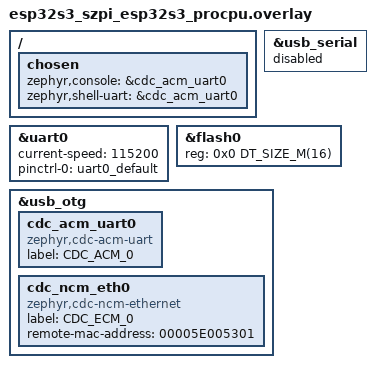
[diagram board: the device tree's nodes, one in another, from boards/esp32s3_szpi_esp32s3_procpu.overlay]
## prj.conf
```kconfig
CONFIG_NETWORKING=y
CONFIG_NET_ZPERF=y
CONFIG_NET_ZPERF_SERVER=y
CONFIG_NET_LOG=y
CONFIG_NET_IPV6=y
CONFIG_NET_IPV4=y
CONFIG_NET_DHCPV4=n
CONFIG_NET_UDP=y
CONFIG_NET_TCP=y
CONFIG_NET_TCP_IPV6_ND_REACHABILITY_HINT=y
CONFIG_NET_STATISTICS=y

CONFIG_NET_PKT_RX_COUNT=40
CONFIG_NET_PKT_TX_COUNT=40
CONFIG_NET_BUF_RX_COUNT=160
CONFIG_NET_BUF_TX_COUNT=160
CONFIG_NET_BUF_DATA_SIZE=256
CONFIG_NET_IF_UNICAST_IPV6_ADDR_COUNT=4
CONFIG_NET_IF_MCAST_IPV6_ADDR_COUNT=5
CONFIG_NET_IF_UNICAST_IPV4_ADDR_COUNT=1
CONFIG_NET_MAX_CONTEXTS=5
CONFIG_NET_TC_TX_COUNT=1
CONFIG_NET_SOCKETS=y
CONFIG_NET_SOCKETS_SERVICE_THREAD_PRIO=-1
CONFIG_ZVFS_POLL_MAX=9

CONFIG_INIT_STACKS=y
CONFIG_TEST_RANDOM_GENERATOR=y

CONFIG_NET_L2_ETHERNET=y
CONFIG_NET_SHELL=y

CONFIG_NET_CONFIG_SETTINGS=y
CONFIG_NET_CONFIG_MY_IPV6_ADDR="2001:db8::1"
CONFIG_NET_CONFIG_PEER_IPV6_ADDR="2001:db8::2"
CONFIG_NET_CONFIG_MY_IPV4_ADDR="192.0.2.1"
CONFIG_NET_CONFIG_PEER_IPV4_ADDR="192.0.2.2"

CONFIG_LOG=y
CONFIG_SHELL_CMDS_RESIZE=n

CONFIG_CACHE_MANAGEMENT=y
CONFIG_SPEED_OPTIMIZATIONS=y
CONFIG_TIMESLICING=n

# For speed optimizations
CONFIG_PICOLIBC_USE_MODULE=y


CONFIG_UDC_DWC2_DMA=n
```

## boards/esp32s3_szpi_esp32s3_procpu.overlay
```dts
/ {
	chosen {
		zephyr,console = &cdc_acm_uart0;
		zephyr,shell-uart = &cdc_acm_uart0;
	};
};

&usb_serial {
	status = "disabled";
};

&uart0 {
	status = "okay";
	current-speed = <115200>;
	pinctrl-0 = <&uart0_default>;
	pinctrl-names = "default";
};

&flash0 {
    reg = <0x0 DT_SIZE_M(16)>;
};

zephyr_udc0: &usb_otg {
	status = "okay";

    cdc_acm_uart0: cdc_acm_uart0 {
        compatible = "zephyr,cdc-acm-uart";
        label = "CDC_ACM_0";
    };

    cdc_ncm_eth0: cdc_ncm_eth0 {
        label = "CDC_ECM_0";
		compatible = "zephyr,cdc-ncm-ethernet";
		remote-mac-address = "00005E005301";
	};

};
```

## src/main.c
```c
/*
 * Copyright (c) 2020 Nordic Semiconductor ASA
 *
 * SPDX-License-Identifier: Apache-2.0
 */

/**
 * @file
 * @brief Zperf sample.
 */
#include <zephyr/usb/usbd.h>
#include <zephyr/net/net_config.h>

LOG_MODULE_REGISTER(zperf, CONFIG_NET_ZPERF_LOG_LEVEL);

#ifdef CONFIG_NET_LOOPBACK_SIMULATE_PACKET_DROP
#include <zephyr/net/loopback.h>
#endif

#if defined(CONFIG_USB_DEVICE_STACK_NEXT)
#include <sample_usbd.h>
#endif

int main(void)
{
#if defined(CONFIG_USB_DEVICE_STACK_NEXT)
	struct usbd_context *sample_usbd;
	int err;

    printk("USB DEV ---->\n\r");

	sample_usbd = sample_usbd_init_device(NULL);
	if (sample_usbd == NULL) {
		return -ENODEV;
	}

	err = usbd_enable(sample_usbd);
	if (err) {
		return err;
	}

	(void)net_config_init_app(NULL, "Initializing network");
#endif /* CONFIG_USB_DEVICE_STACK_NEXT */

#ifdef CONFIG_NET_LOOPBACK_SIMULATE_PACKET_DROP
	loopback_set_packet_drop_ratio(1);
#endif

#if defined(CONFIG_NET_DHCPV4) && !defined(CONFIG_NET_CONFIG_SETTINGS)
	net_dhcpv4_start(net_if_get_default());
#endif
	return 0;
}
```
